AUTOSAR XML (schema 00051)
package /Components
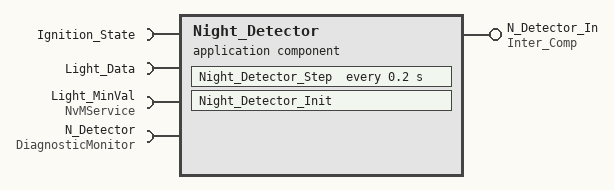
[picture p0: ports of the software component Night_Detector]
  application sw component type Night_Detector
    require port Ignition_State: nonqueued-receiver-com-spec{data-element=Value, init-value=0}, required-interface=Ignition_State
    require port Light_Data: nonqueued-receiver-com-spec{data-element=Value, init-value=0}, required-interface=Light_Data
    provide port N_Detector_In: nonqueued-sender-com-spec{data-element=Value, init-value=0}, provided-interface=Inter_Comp
    require port Light_MinVal: required-interface=NvMService
    require port N_Detector: required-interface=DiagnosticMonitor
    behavior Night_Detector_IB: data-type-mapping=dictDataTypeMappingsSet, handle-termination-and-restart=NO-SUPPORT
      timing event Event_Night_Detector_Step: start-on-event=Night_Detector_Step, period=0.2
      runnable Night_Detector_Init
        async call SC_Light_MinVal_ReadBlock: operation=Light_MinVal.ReadBlock, timeout=1
      runnable Night_Detector_Step
        data-read-access:
          access IN_Light_Data_Value: accessed-variable=Light_Data.Value
          access IN_Ignition_State_Value: accessed-variable=Ignition_State.Value
        data-write-access:
          access OUT_N_Detector_In_Value: accessed-variable=N_Detector_In.Value
        sync call SC_N_Detector_SetEventStatus: operation=N_Detector.SetEventStatus, timeout=1.0E-06
